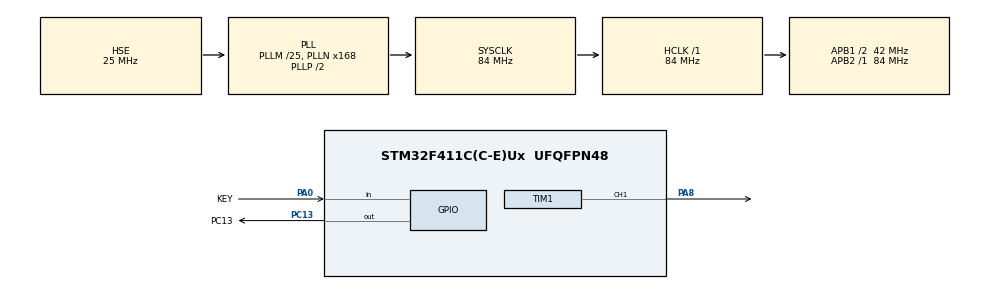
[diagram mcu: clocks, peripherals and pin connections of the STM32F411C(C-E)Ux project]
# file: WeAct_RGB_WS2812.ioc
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Dma.MEMTOMEM.0.Direction=DMA_MEMORY_TO_MEMORY
Dma.MEMTOMEM.0.FIFOMode=DMA_FIFOMODE_ENABLE
Dma.MEMTOMEM.0.FIFOThreshold=DMA_FIFO_THRESHOLD_FULL
Dma.MEMTOMEM.0.Instance=DMA2_Stream0
Dma.MEMTOMEM.0.MemBurst=DMA_MBURST_SINGLE
Dma.MEMTOMEM.0.MemDataAlignment=DMA_MDATAALIGN_BYTE
Dma.MEMTOMEM.0.MemInc=DMA_MINC_ENABLE
Dma.MEMTOMEM.0.Mode=DMA_NORMAL
Dma.MEMTOMEM.0.PeriphBurst=DMA_PBURST_SINGLE
Dma.MEMTOMEM.0.PeriphDataAlignment=DMA_PDATAALIGN_BYTE
Dma.MEMTOMEM.0.PeriphInc=DMA_PINC_ENABLE
Dma.MEMTOMEM.0.Priority=DMA_PRIORITY_MEDIUM
Dma.Request0=MEMTOMEM
Dma.Request1=TIM1_CH1
Dma.TIM1_CH1.1.Direction=DMA_MEMORY_TO_PERIPH
Dma.TIM1_CH1.1.FIFOMode=DMA_FIFOMODE_DISABLE
Dma.TIM1_CH1.1.Instance=DMA2_Stream1
Dma.TIM1_CH1.1.MemDataAlignment=DMA_MDATAALIGN_HALFWORD
Dma.TIM1_CH1.1.MemInc=DMA_MINC_ENABLE
Dma.TIM1_CH1.1.Mode=DMA_NORMAL
Dma.TIM1_CH1.1.PeriphDataAlignment=DMA_PDATAALIGN_HALFWORD
Dma.TIM1_CH1.1.PeriphInc=DMA_PINC_DISABLE
Dma.TIM1_CH1.1.Priority=DMA_PRIORITY_LOW
Mcu.Family=STM32F4
Mcu.Name=STM32F411C(C-E)Ux
Mcu.Package=UFQFPN48
NVIC.DMA2_Stream1_IRQn=true\:0\:0\:false\:false\:true\:false\:true
NVIC.PriorityGroup=NVIC_PRIORITYGROUP_4
NVIC.TIM1_CC_IRQn=true\:0\:0\:false\:false\:true\:true\:true
PA0-WKUP.GPIO_Label=KEY
PA0-WKUP.GPIO_PuPd=GPIO_PULLUP
PA0-WKUP.Signal=GPIO_Input
PA13.Mode=Serial_Wire
PA13.Signal=SYS_JTMS-SWDIO
PA14.Mode=Serial_Wire
PA14.Signal=SYS_JTCK-SWCLK
PA8.GPIO_PuPd=GPIO_PULLDOWN
PA8.Signal=S_TIM1_CH1
PC13-ANTI_TAMP.GPIO_Label=PC13
PC13-ANTI_TAMP.PinState=GPIO_PIN_SET
PC13-ANTI_TAMP.Signal=GPIO_Output
PC14-OSC32_IN.Mode=LSE-External-Oscillator
PC14-OSC32_IN.Signal=RCC_OSC32_IN
PC15-OSC32_OUT.Mode=LSE-External-Oscillator
PC15-OSC32_OUT.Signal=RCC_OSC32_OUT
PH0\ -\ OSC_IN.Mode=HSE-External-Oscillator
PH0\ -\ OSC_IN.Signal=RCC_OSC_IN
PH1\ -\ OSC_OUT.Mode=HSE-External-Oscillator
PH1\ -\ OSC_OUT.Signal=RCC_OSC_OUT
ProjectManager.HeapSize=0x200
ProjectManager.StackSize=0x400
ProjectManager.TargetToolchain=MDK-ARM V5.27
RCC.48MHZClocksFreq_Value=42000000
RCC.AHBFreq_Value=84000000
RCC.APB1CLKDivider=RCC_HCLK_DIV2
RCC.APB1Freq_Value=42000000
RCC.APB1TimFreq_Value=84000000
RCC.APB2Freq_Value=84000000
RCC.APB2TimFreq_Value=84000000
RCC.CortexFreq_Value=84000000
RCC.HCLKFreq_Value=84000000
RCC.HSE_VALUE=25000000
RCC.HSI_VALUE=16000000
RCC.PLLM=25
RCC.PLLN=168
RCC.PLLSourceVirtual=RCC_PLLSOURCE_HSE
RCC.RCC_RTC_Clock_Source=RCC_RTCCLKSOURCE_LSE
RCC.RCC_RTC_Clock_SourceVirtual=RCC_RTCCLKSOURCE_LSE
RCC.SYSCLKFreq_VALUE=84000000
RCC.SYSCLKSource=RCC_SYSCLKSOURCE_PLLCLK
RCC.VCOOutputFreq_Value=168000000
SH.S_TIM1_CH1.0=TIM1_CH1,PWM Generation1 CH1
TIM1.Channel-PWM\ Generation1\ CH1=TIM_CHANNEL_1
TIM1.Period=105-1
TIM1.Prescaler=1-1
VP_RTC_VS_RTC_Activate.Mode=RTC_Enabled
VP_RTC_VS_RTC_Calendar.Mode=RTC_Calendar
board=custom

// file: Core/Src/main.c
/* USER CODE BEGIN Header */
/**
  ******************************************************************************
  * @file           : main.c
  * @brief          : Main program body
  ******************************************************************************
  * @attention
  *
  * <h2><center>&copy; Copyright (c) 2021 STMicroelectronics.
  * All rights reserved.</center></h2>
  *
  * This software component is licensed by ST under BSD 3-Clause license,
  * the "License"; You may not use this file except in compliance with the
  * License. You may obtain a copy of the License at:
  *                        opensource.org/licenses/BSD-3-Clause
  *
  ******************************************************************************
  */
/* USER CODE END Header */
#include "main.h"
#include "dma.h"
#include "rtc.h"
#include "tim.h"
#include "gpio.h"

void SystemClock_Config(void);
/* USER CODE BEGIN PFP */
static void LED_Blink(uint32_t Hdelay,uint32_t Ldelay)
{
	HAL_GPIO_WritePin(PC13_GPIO_Port,PC13_Pin,GPIO_PIN_RESET);
	HAL_Delay(Hdelay - 1);
	HAL_GPIO_WritePin(PC13_GPIO_Port,PC13_Pin,GPIO_PIN_SET);
	HAL_Delay(Ldelay-1);
}
/* USER CODE END PFP */

/* USER CODE BEGIN 0 */
#define PIXEL_NUM  1
#define BUFFER_NUM (24*PIXEL_NUM + 320)  // 320*11.9nS RESET time
#define WS2812_BIT0   (25)
#define WS2812_BIT1   (65)

uint16_t ws2812_data[BUFFER_NUM];
uint8_t ws2812_brightness;

void HAL_TIM_PWM_PulseFinishedCallback(TIM_HandleTypeDef *htim)
{
  HAL_TIM_PWM_Stop_DMA(&htim1,TIM_CHANNEL_1);
}

void WS_Load(void)
{
	HAL_TIM_PWM_Start_DMA(&htim1,TIM_CHANNEL_1,(uint32_t *)&ws2812_data,sizeof(ws2812_data)/sizeof(uint16_t));
}

void WS_CloseAll(void)
{
	uint16_t i;
	for (i = 0; i < PIXEL_NUM * 24; i++)
		ws2812_data[i] = WS2812_BIT0;
	for (i = PIXEL_NUM * 24; i < BUFFER_NUM; i++)
		ws2812_data[i] = 0;
	HAL_TIM_PWM_Start_DMA(&htim1,TIM_CHANNEL_1,(uint32_t *)&ws2812_data,sizeof(ws2812_data)/sizeof(uint16_t));
}

void WS_WriteAll_RGB(uint8_t n_R, uint8_t n_G, uint8_t n_B)
{
	uint16_t i, j;
	uint8_t dat[24];
	for (i = 0; i < 8; i++)
	{
		dat[i] = ((n_G & 0x80) ? WS2812_BIT1 : WS2812_BIT0);
		n_G <<= 1;
	}
	for (i = 0; i < 8; i++)
	{
		dat[i + 8] = ((n_R & 0x80) ? WS2812_BIT1 : WS2812_BIT0);
		n_R <<= 1;
	}
	for (i = 0; i < 8; i++)
	{
		dat[i + 16] = ((n_B & 0x80) ? WS2812_BIT1 : WS2812_BIT0);
		n_B <<= 1;
	}
	for (i = 0; i < PIXEL_NUM; i++)
	{
		for (j = 0; j < 24; j++)
		{
			ws2812_data[i * 24 + j] = dat[j];
		}
	}
	for (i = PIXEL_NUM * 24; i < BUFFER_NUM; i++)
		ws2812_data[i] = 0;
	WS_Load();
}

uint32_t WS281x_Color(uint8_t red, uint8_t green, uint8_t blue)
{
  if(ws2812_brightness) {
      red = (red * ws2812_brightness) >> 8;
      green = (green * ws2812_brightness) >> 8;
      blue = (blue * ws2812_brightness) >> 8;
  }
  else
  {
    red = 0;
    green = 0;
    blue = 0;
  }
	return green << 16 | red << 8 | blue;
}

void WS281x_SetPixelColor(uint16_t n, uint32_t GRBColor)
{
	uint8_t i;
	if (n < PIXEL_NUM)
	{
		for (i = 0; i < 24; ++i)
			ws2812_data[24 * n + i] = (((GRBColor << i) & 0X800000) ? WS2812_BIT1 : WS2812_BIT0);
	}
}

void WS281x_SetPixelRGB(uint16_t n, uint8_t red, uint8_t green, uint8_t blue)
{
	uint8_t i;

	if (n < PIXEL_NUM)
	{
		for (i = 0; i < 24; ++i)
			ws2812_data[24 * n + i] = (((WS281x_Color(red, green, blue) << i) & 0X800000) ? WS2812_BIT1 : WS2812_BIT0);
	}
}

uint32_t Wheel(uint8_t WheelPos)
{
	WheelPos = 255 - WheelPos;
	if (WheelPos < 85)
	{
		return WS281x_Color(255 - WheelPos * 3, 0, WheelPos * 3);
	}
	if (WheelPos < 170)
	{
		WheelPos -= 85;
		return WS281x_Color(0, WheelPos * 3, 255 - WheelPos * 3);
	}
	WheelPos -= 170;
	return WS281x_Color(WheelPos * 3, 255 - WheelPos * 3, 0);
}

void rainbow(uint8_t wait)
{
	uint32_t timestamp = HAL_GetTick();
	uint16_t i;
	static uint8_t j;
	static uint32_t next_time = 0;

	uint32_t flag = 0;
	if (next_time < wait)
	{
		if ((uint64_t)timestamp + wait - next_time > 0)
			flag = 1;
	}
	else if (timestamp > next_time)
	{
		flag = 1;
	}
	if (flag) // && (timestamp - next_time < wait*5))
	{
		j++;
		next_time = timestamp + wait;
		for (i = 0; i < PIXEL_NUM; i++)
		{
			WS281x_SetPixelColor(i, Wheel((i + j) & 255));
		}
	}
	WS_Load();
}

void rainbowCycle(uint8_t wait)
{
	uint32_t timestamp = HAL_GetTick();
	uint16_t i;
	static uint8_t j;
	static uint32_t next_time = 0;

	static uint8_t loop = 0;
	if (loop == 0)
		next_time = timestamp;
	loop = 1; //???????

	if ((timestamp > next_time)) // && (timestamp - next_time < wait*5))
	{
		j++;
		next_time = timestamp + wait;
		for (i = 0; i < PIXEL_NUM; i++)
		{
			WS281x_SetPixelColor(i, Wheel(((i * 256 / (PIXEL_NUM)) + j) & 255));
		}
	}
	WS_Load();
}

uint8_t r,g,b;
/* USER CODE END 0 */

int main(void)
{
  /* USER CODE BEGIN 1 */
  uint8_t time_delay;
  /* USER CODE END 1 */

  /* MCU Configuration--------------------------------------------------------*/

  /* Reset of all peripherals, Initializes the Flash interface and the Systick. */
  HAL_Init();

  /* Configure the system clock */
  SystemClock_Config();

  /* Initialize all configured peripherals */
  MX_GPIO_Init();
  MX_DMA_Init();
  MX_RTC_Init();
  MX_TIM1_Init();
  /* USER CODE BEGIN 2 */
  WS_CloseAll();
  ws2812_brightness = 25;
  time_delay = 10;
  /* USER CODE END 2 */

  /* Infinite loop */
  /* USER CODE BEGIN WHILE */
  while (1)
  {
    if(HAL_GPIO_ReadPin(KEY_GPIO_Port,KEY_Pin) != GPIO_PIN_SET)
    {
      while(HAL_GPIO_ReadPin(KEY_GPIO_Port,KEY_Pin) != GPIO_PIN_SET)
      {
        LED_Blink(5,300);
      }
      time_delay += 5;
      if(time_delay > 50) time_delay = 0;
    }
    // WS_WriteAll_RGB(r,g,b);
    rainbowCycle(time_delay);
    /* USER CODE END WHILE */

  }
}

void SystemClock_Config(void)
{
  RCC_OscInitTypeDef RCC_OscInitStruct = {0};
  RCC_ClkInitTypeDef RCC_ClkInitStruct = {0};
  RCC_PeriphCLKInitTypeDef PeriphClkInitStruct = {0};

  /** Configure the main internal regulator output voltage
  */
  __HAL_RCC_PWR_CLK_ENABLE();
  __HAL_PWR_VOLTAGESCALING_CONFIG(PWR_REGULATOR_VOLTAGE_SCALE1);
  /** Initializes the RCC Oscillators according to the specified parameters
  * in the RCC_OscInitTypeDef structure.
  */
  RCC_OscInitStruct.OscillatorType = RCC_OSCILLATORTYPE_HSE|RCC_OSCILLATORTYPE_LSE;
  RCC_OscInitStruct.HSEState = RCC_HSE_ON;
  RCC_OscInitStruct.LSEState = RCC_LSE_ON;
  RCC_OscInitStruct.PLL.PLLState = RCC_PLL_ON;
  RCC_OscInitStruct.PLL.PLLSource = RCC_PLLSOURCE_HSE;
  RCC_OscInitStruct.PLL.PLLM = 25;
  RCC_OscInitStruct.PLL.PLLN = 168;
  RCC_OscInitStruct.PLL.PLLP = RCC_PLLP_DIV2;
  RCC_OscInitStruct.PLL.PLLQ = 4;
  if (HAL_RCC_OscConfig(&RCC_OscInitStruct) != HAL_OK)
  {
    Error_Handler();
  }
  /** Initializes the CPU, AHB and APB buses clocks
  */
  RCC_ClkInitStruct.ClockType = RCC_CLOCKTYPE_HCLK|RCC_CLOCKTYPE_SYSCLK
                              |RCC_CLOCKTYPE_PCLK1|RCC_CLOCKTYPE_PCLK2;
  RCC_ClkInitStruct.SYSCLKSource = RCC_SYSCLKSOURCE_PLLCLK;
  RCC_ClkInitStruct.AHBCLKDivider = RCC_SYSCLK_DIV1;
  RCC_ClkInitStruct.APB1CLKDivider = RCC_HCLK_DIV2;
  RCC_ClkInitStruct.APB2CLKDivider = RCC_HCLK_DIV1;

  if (HAL_RCC_ClockConfig(&RCC_ClkInitStruct, FLASH_LATENCY_2) != HAL_OK)
  {
    Error_Handler();
  }
  PeriphClkInitStruct.PeriphClockSelection = RCC_PERIPHCLK_RTC;
  PeriphClkInitStruct.RTCClockSelection = RCC_RTCCLKSOURCE_LSE;
  if (HAL_RCCEx_PeriphCLKConfig(&PeriphClkInitStruct) != HAL_OK)
  {
    Error_Handler();
  }
}

void Error_Handler(void)
{
  __disable_irq();
  while (1)
  {
  }
}

/************************ (C) COPYRIGHT STMicroelectronics *****END OF FILE****/
